# MSS_IOMUX register map
Vendor: Texas Instruments
Peripheral module from a debugger description file (folder radar).
Registers are 32-bit, read-write, no defined reset value unless marked. A register's access mark holds for its fields unless they carry their own. Offsets are as the file gives them; lines under a group give offsets from that group; [hi:lo] are bit positions; {n}, {i} and the like mark numbered series; 'fields as' and 'values as' point back to an identical list; <NAME> marks a mode.

## MSS_IOMUX
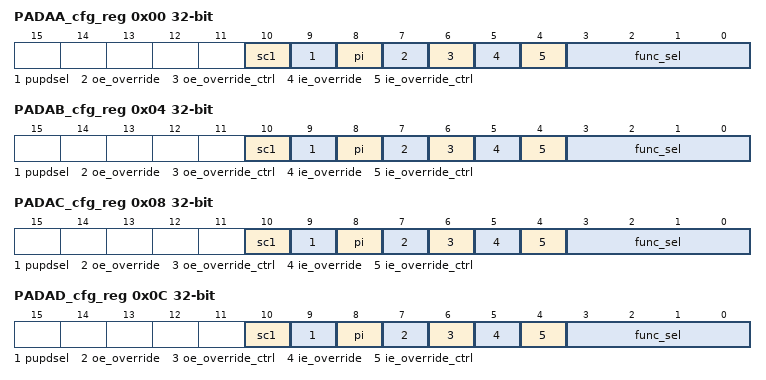
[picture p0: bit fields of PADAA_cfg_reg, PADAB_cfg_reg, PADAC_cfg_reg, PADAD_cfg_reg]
0x00 PADAA_cfg_reg
  [10] sc1 — IO Slew rate control : 0 : higher slew rate. 1: Lower slew rate.
  [9] pupdsel — Pullup/PullDown Selection 0 -- Pull Down ; 1 -- Pull Up (This field is valid only if pi is enabled)
  [8] pi — Pull Inhibit/Pull Disable 0 -- Enable ; 1 -- Disable
  [7] oe_override — Active Low Output Override
  [6] oe_override_ctrl — Active Low Output Override Control : Write 1 to select Active low Output Override value to control IOs OE_N/GZ instead of the control from hardware
  [5] ie_override — Active Low Input Override
  [4] ie_override_ctrl — Active Low Input Override Control : Write 1 to select Active low Input Override value to control IOs IE_N/RXACTIVE_N instead of the control from hardware
  [3:0] func_sel — Function select
0x04 PADAB_cfg_reg
  fields as PADAA_cfg_reg
0x08 PADAC_cfg_reg
  fields as PADAA_cfg_reg
0x0C PADAD_cfg_reg
  fields as PADAA_cfg_reg
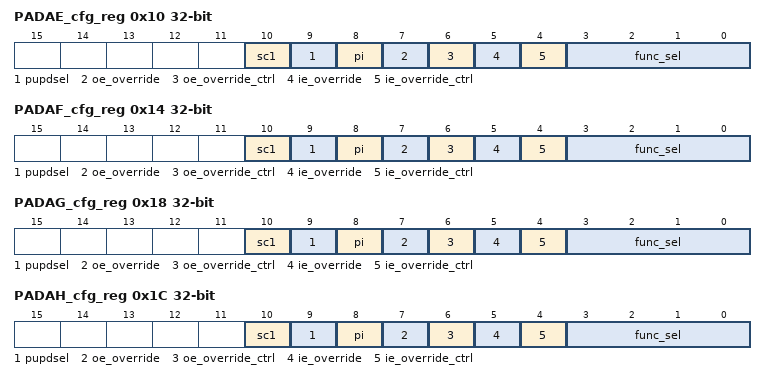
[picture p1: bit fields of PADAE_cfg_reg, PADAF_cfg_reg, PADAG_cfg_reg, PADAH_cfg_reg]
0x10 PADAE_cfg_reg
  fields as PADAA_cfg_reg
0x14 PADAF_cfg_reg
  fields as PADAA_cfg_reg
0x18 PADAG_cfg_reg
  fields as PADAA_cfg_reg
0x1C PADAH_cfg_reg
  fields as PADAA_cfg_reg
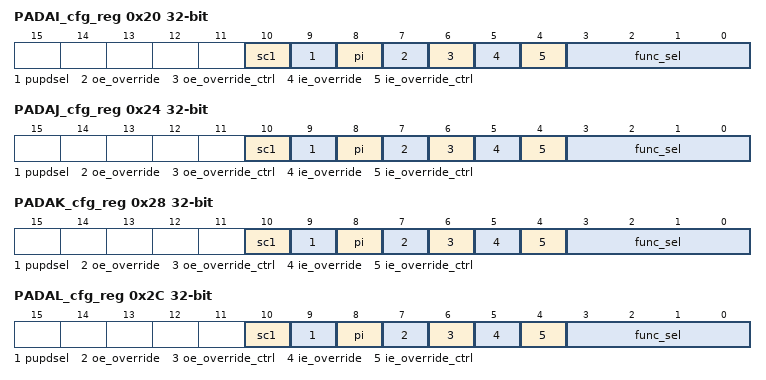
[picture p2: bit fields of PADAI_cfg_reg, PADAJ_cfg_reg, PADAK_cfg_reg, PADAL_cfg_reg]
0x20 PADAI_cfg_reg
  fields as PADAA_cfg_reg
0x24 PADAJ_cfg_reg
  fields as PADAA_cfg_reg
0x28 PADAK_cfg_reg
  fields as PADAA_cfg_reg
0x2C PADAL_cfg_reg
  fields as PADAA_cfg_reg
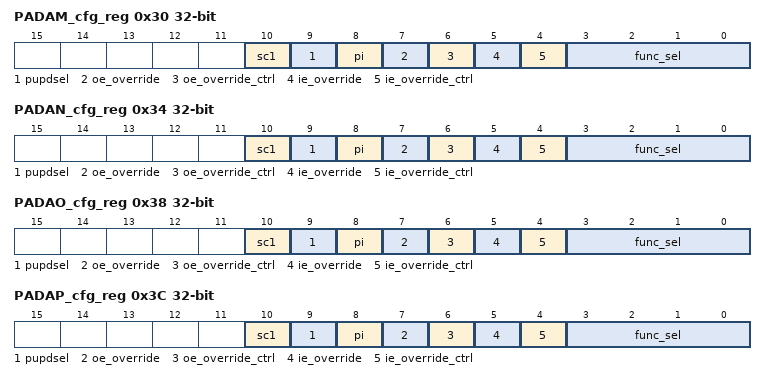
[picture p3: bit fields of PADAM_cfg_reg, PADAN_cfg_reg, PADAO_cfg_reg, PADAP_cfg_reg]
0x30 PADAM_cfg_reg
  fields as PADAA_cfg_reg
0x34 PADAN_cfg_reg
  fields as PADAA_cfg_reg
0x38 PADAO_cfg_reg
  fields as PADAA_cfg_reg
0x3C PADAP_cfg_reg
  fields as PADAA_cfg_reg
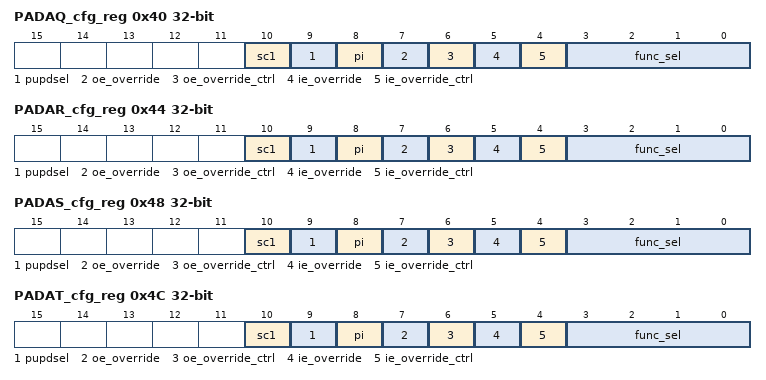
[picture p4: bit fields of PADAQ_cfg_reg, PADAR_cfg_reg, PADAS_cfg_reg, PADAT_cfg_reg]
0x40 PADAQ_cfg_reg
  fields as PADAA_cfg_reg
0x44 PADAR_cfg_reg
  fields as PADAA_cfg_reg
0x48 PADAS_cfg_reg
  fields as PADAA_cfg_reg
0x4C PADAT_cfg_reg
  fields as PADAA_cfg_reg
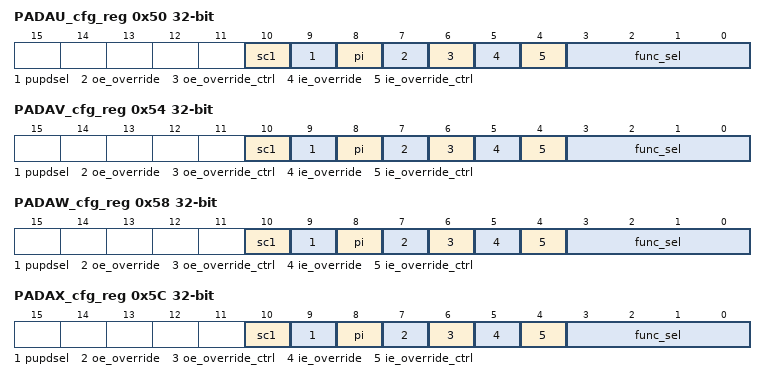
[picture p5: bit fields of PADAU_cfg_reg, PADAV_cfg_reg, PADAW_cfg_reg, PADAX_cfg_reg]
0x50 PADAU_cfg_reg
  fields as PADAA_cfg_reg
0x54 PADAV_cfg_reg
  fields as PADAA_cfg_reg
0x58 PADAW_cfg_reg
  fields as PADAA_cfg_reg
0x5C PADAX_cfg_reg
  fields as PADAA_cfg_reg
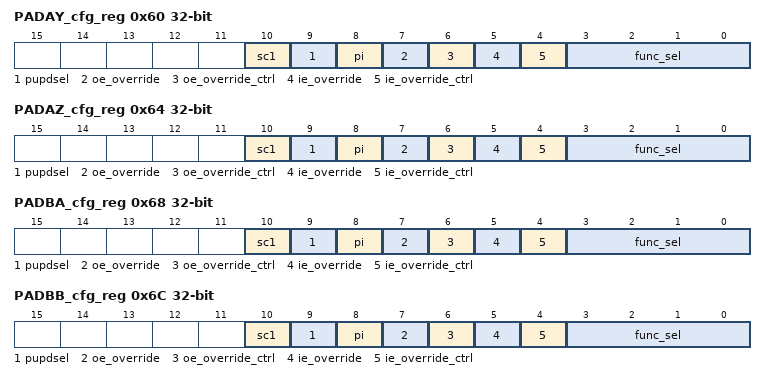
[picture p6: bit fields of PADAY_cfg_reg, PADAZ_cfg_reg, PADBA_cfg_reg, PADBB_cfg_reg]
0x60 PADAY_cfg_reg
  fields as PADAA_cfg_reg
0x64 PADAZ_cfg_reg
  fields as PADAA_cfg_reg
0x68 PADBA_cfg_reg
  fields as PADAA_cfg_reg
0x6C PADBB_cfg_reg
  fields as PADAA_cfg_reg
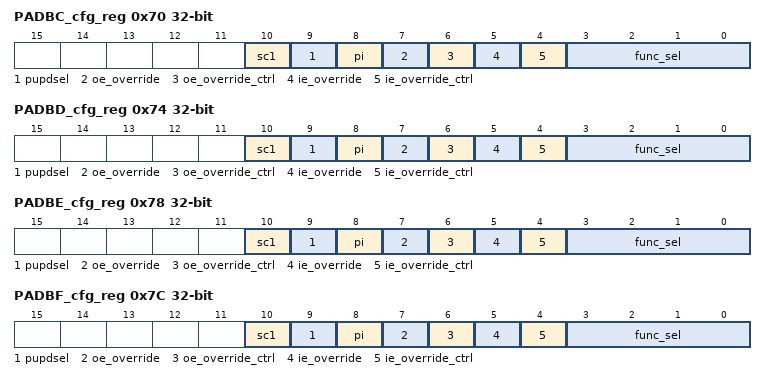
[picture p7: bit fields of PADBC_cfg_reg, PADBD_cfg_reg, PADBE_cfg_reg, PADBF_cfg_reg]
0x70 PADBC_cfg_reg
  fields as PADAA_cfg_reg
0x74 PADBD_cfg_reg
  fields as PADAA_cfg_reg
0x78 PADBE_cfg_reg
  fields as PADAA_cfg_reg
0x7C PADBF_cfg_reg
  fields as PADAA_cfg_reg
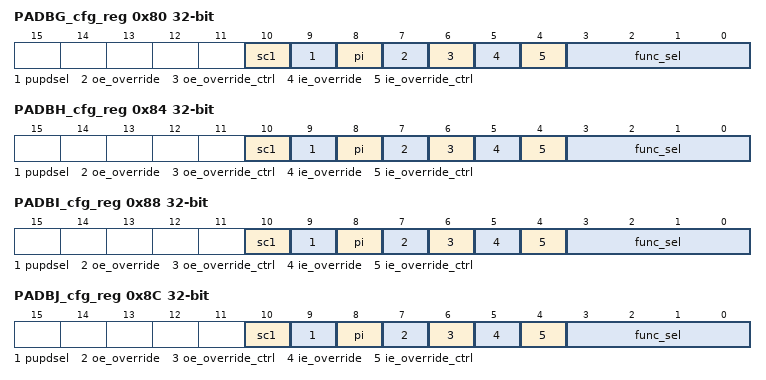
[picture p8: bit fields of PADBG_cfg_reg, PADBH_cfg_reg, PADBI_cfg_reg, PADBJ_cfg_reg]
0x80 PADBG_cfg_reg
  fields as PADAA_cfg_reg
0x84 PADBH_cfg_reg
  fields as PADAA_cfg_reg
0x88 PADBI_cfg_reg
  fields as PADAA_cfg_reg
0x8C PADBJ_cfg_reg
  fields as PADAA_cfg_reg
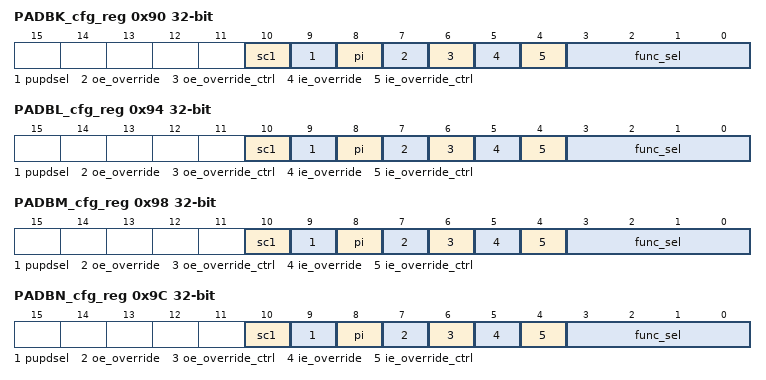
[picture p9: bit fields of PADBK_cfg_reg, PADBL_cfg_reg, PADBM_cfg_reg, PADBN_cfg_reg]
0x90 PADBK_cfg_reg
  fields as PADAA_cfg_reg
0x94 PADBL_cfg_reg
  fields as PADAA_cfg_reg
0x98 PADBM_cfg_reg
  fields as PADAA_cfg_reg
0x9C PADBN_cfg_reg
  fields as PADAA_cfg_reg
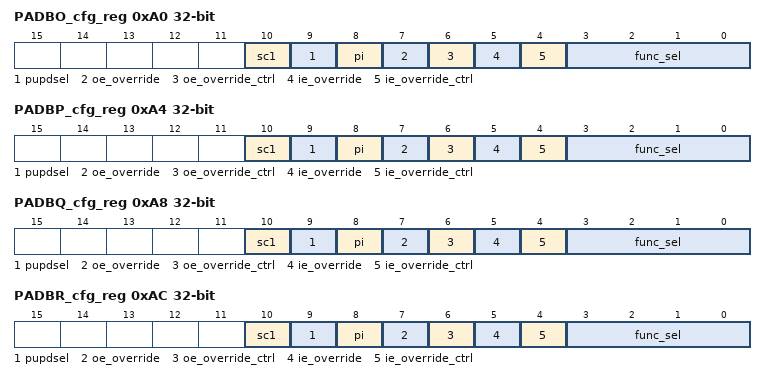
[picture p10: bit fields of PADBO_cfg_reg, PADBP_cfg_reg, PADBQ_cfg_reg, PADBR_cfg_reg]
0xA0 PADBO_cfg_reg
  fields as PADAA_cfg_reg
0xA4 PADBP_cfg_reg
  fields as PADAA_cfg_reg
0xA8 PADBQ_cfg_reg
  fields as PADAA_cfg_reg
0xAC PADBR_cfg_reg
  fields as PADAA_cfg_reg
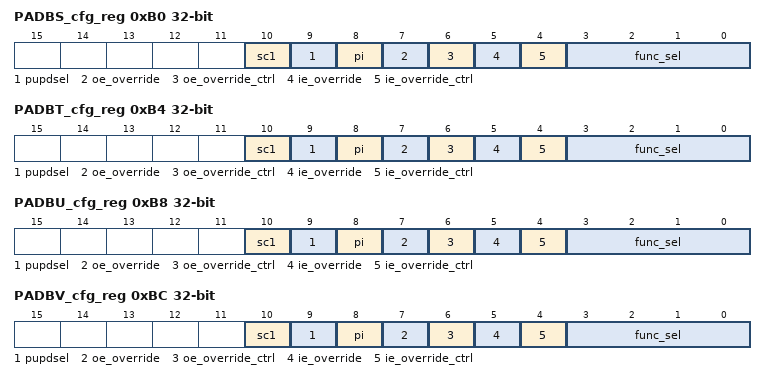
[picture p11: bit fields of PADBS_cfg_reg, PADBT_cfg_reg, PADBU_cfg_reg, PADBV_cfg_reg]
0xB0 PADBS_cfg_reg
  [10] sc1 — IO Slew rate control : 0 : higher slew rate. 1: Lower slew rate.
  [9] pupdsel — Pullup/PullDown Selection 0 -- Pull Down ; 1 -- Pull Up (This field is valid only if pi is enabled)
  [8] pi — Pull Inhibit/Pull Disable 0 -- Enable ; 1 -- Disable
  [7] oe_override — Active Low Output Override
  [6] oe_override_ctrl — Active Low Output Override Control : Write 1 to select Active low Output Override value to control IOs OE_N/GZ instead of the control from hardware
  [5] ie_override — Input Override
  [4] ie_override_ctrl — Active Low Input Override Control : Write 1 to select Active low Input Override value to control IOs IE_N/RXACTIVE_N instead of the control from hardware
  [3:0] func_sel — Function select
0xB4 PADBT_cfg_reg
  fields as PADAA_cfg_reg
0xB8 PADBU_cfg_reg
  fields as PADAA_cfg_reg
0xBC PADBV_cfg_reg
  fields as PADAA_cfg_reg
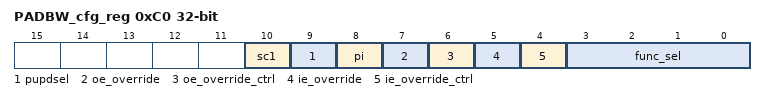
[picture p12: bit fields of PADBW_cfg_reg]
0xC0 PADBW_cfg_reg
  fields as PADAA_cfg_reg
0x1F0 USERMODEEN
  [31:0] USERMODEEN — Write 0XADADADAD to enable user mode write access to IO CFG space.
0x1F4 PADGLBLCFGREG
  [31:0] PADGLBLCFGREG — 2:0 : global_ie_n_ctl - Write 3'b111 to pass global_ie_n_val to IE_N/RXACTIVE_N pin of all the IOs. 3 : global_ie_n_val - Active low 10:8 : global_oe_n_ctl - Write 3'b111 to pass global_oe_n_val to OE_N/GZ pin of all the IOs. 11 : global_oe_n_val - Active low 18:16 : global_pi_ctl - Write 3'b111 to pass global_pi_val and global_pu_val to all the IOs 19 : global_pi_val 20 : global_pu_val
0x1F8 IOCFGKICK0
  [31:0] IOCFGKICK0 — Kicker 0 Register. The value 83E7 0B13h must be written to KICK0 as part of the process to unlock the CPU write access to the above PIN MUX registers (including IOCFGKICK1)
0x1FC IOCFGKICK1
  [31:0] IOCFGKICK1 — Kicker 1 Register. The value 95A4 F1E0h must be written to the KICK1 as part of the process to unlock the CPU write access to above PINMUX registers (excluding IOCFGKICK0). IOCFGKICK0 has to be written with 83E70B13h to enable access to IOCFGKICK1.
